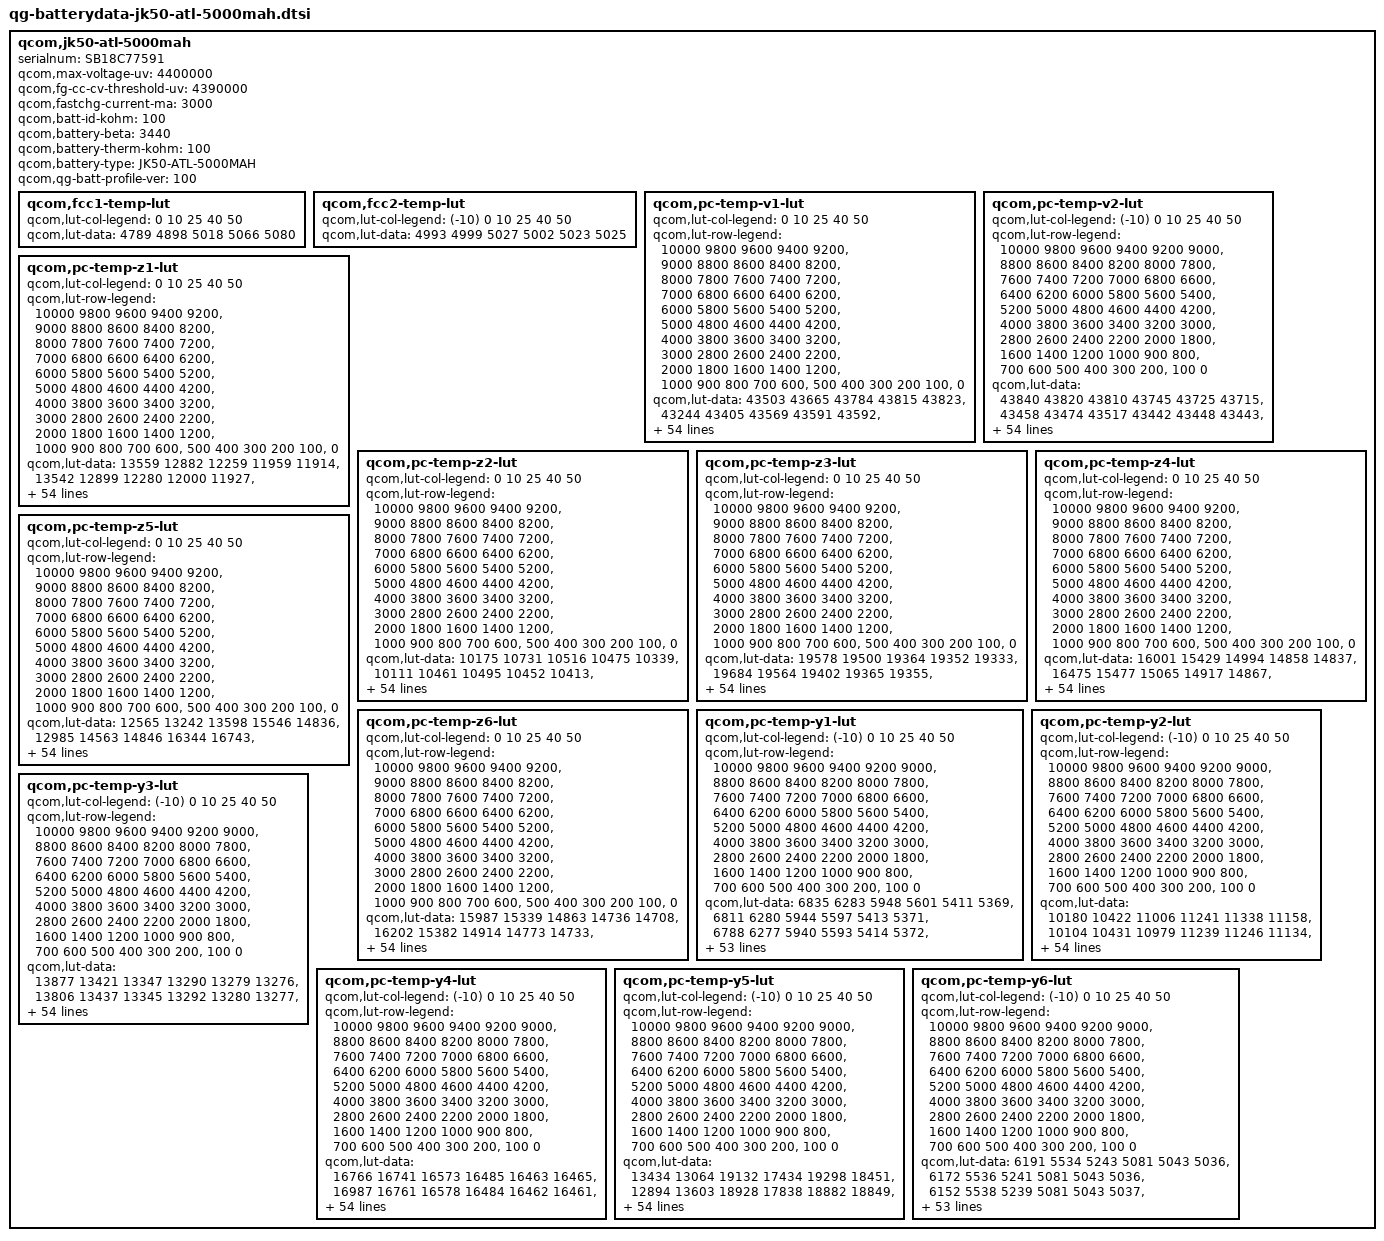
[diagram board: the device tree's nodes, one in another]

qcom,jk50-atl-5000mah {
    /* 4614914_Huaqin_QL1899_MOTO_5000mAH_PMI632_averaged_MasterSlave_Jun15th2020 */
    serialnum = "SB18C77591";
    qcom,max-voltage-uv = <4400000>;
    qcom,fg-cc-cv-threshold-uv = <4390000>;
    qcom,fastchg-current-ma = <3000>;
    qcom,batt-id-kohm = <100>;
    qcom,battery-beta = <3440>;
    qcom,battery-therm-kohm = <100>;
    qcom,battery-type = "JK50-ATL-5000MAH";
    qcom,qg-batt-profile-ver = <100>;

	qcom,fcc1-temp-lut {
		qcom,lut-col-legend = <0 10 25 40 50>;
		qcom,lut-data = <4789 4898 5018 5066 5080>;
	};

	qcom,fcc2-temp-lut {
		qcom,lut-col-legend = <(-10) 0 10 25 40 50>;
		qcom,lut-data = <4993 4999 5027 5002 5023 5025>;
	};

	qcom,pc-temp-v1-lut {
		qcom,lut-col-legend = <0 10 25 40 50>;
		qcom,lut-row-legend = <10000 9800 9600 9400 9200>,
			<9000 8800 8600 8400 8200>,
			<8000 7800 7600 7400 7200>,
			<7000 6800 6600 6400 6200>,
			<6000 5800 5600 5400 5200>,
			<5000 4800 4600 4400 4200>,
			<4000 3800 3600 3400 3200>,
			<3000 2800 2600 2400 2200>,
			<2000 1800 1600 1400 1200>,
			<1000 900 800 700 600>,
			<500 400 300 200 100>,
			<0>;
		qcom,lut-data = <43503 43665 43784 43815 43823>,
			<43244 43405 43569 43591 43592>,
			<42990 43154 43314 43362 43368>,
			<42743 42911 43067 43131 43145>,
			<42505 42674 42828 42897 42915>,
			<42275 42439 42590 42660 42681>,
			<42049 42209 42357 42426 42448>,
			<41829 41983 42125 42191 42216>,
			<41615 41760 41896 41959 41985>,
			<41412 41542 41666 41732 41754>,
			<41220 41336 41443 41507 41525>,
			<41022 41138 41233 41290 41303>,
			<40809 40935 41033 41076 41087>,
			<40591 40723 40829 40868 40879>,
			<40372 40511 40618 40660 40674>,
			<40149 40304 40412 40457 40476>,
			<39953 40102 40216 40267 40286>,
			<39802 39928 40029 40089 40106>,
			<39673 39786 39866 39919 39933>,
			<39547 39657 39731 39768 39778>,
			<39422 39522 39588 39615 39624>,
			<39301 39385 39390 39404 39423>,
			<39181 39233 39157 39119 39152>,
			<39063 39033 38950 38901 38930>,
			<38949 38821 38755 38775 38799>,
			<38840 38664 38607 38676 38695>,
			<38735 38539 38524 38581 38595>,
			<38633 38446 38464 38493 38502>,
			<38533 38383 38401 38410 38414>,
			<38445 38336 38336 38331 38328>,
			<38376 38294 38277 38258 38248>,
			<38318 38257 38224 38190 38176>,
			<38269 38222 38176 38128 38112>,
			<38231 38189 38132 38071 38049>,
			<38197 38159 38092 38022 37991>,
			<38163 38125 38051 37975 37935>,
			<38132 38089 38010 37927 37878>,
			<38094 38047 37965 37878 37822>,
			<38042 37986 37904 37813 37751>,
			<37976 37903 37818 37719 37656>,
			<37889 37806 37716 37612 37548>,
			<37765 37690 37604 37501 37436>,
			<37625 37555 37474 37376 37312>,
			<37466 37391 37315 37221 37153>,
			<37332 37252 37172 37083 37019>,
			<37235 37163 37080 36998 36939>,
			<37207 37133 37054 36970 36910>,
			<37184 37116 37037 36953 36892>,
			<37154 37091 37019 36933 36872>,
			<37100 37049 36971 36875 36802>,
			<36895 36830 36732 36619 36518>,
			<36447 36388 36298 36181 36077>,
			<35869 35813 35725 35606 35502>,
			<35085 35027 34941 34820 34713>,
			<33848 33792 33723 33601 33485>,
			<30000 30000 30000 30000 30000>;
	};

	qcom,pc-temp-v2-lut {
		qcom,lut-col-legend = <(-10) 0 10 25 40 50>;
		qcom,lut-row-legend = <10000 9800 9600 9400 9200 9000>,
			<8800 8600 8400 8200 8000 7800>,
			<7600 7400 7200 7000 6800 6600>,
			<6400 6200 6000 5800 5600 5400>,
			<5200 5000 4800 4600 4400 4200>,
			<4000 3800 3600 3400 3200 3000>,
			<2800 2600 2400 2200 2000 1800>,
			<1600 1400 1200 1000 900 800>,
			<700 600 500 400 300 200>,
			<100 0>;
		qcom,lut-data = <43840 43820 43810 43745 43725 43715>,
			<43458 43474 43517 43442 43448 43443>,
			<43111 43158 43238 43158 43183 43182>,
			<42801 42876 42974 42897 42931 42934>,
			<42521 42626 42724 42658 42692 42697>,
			<42275 42384 42481 42423 42457 42464>,
			<42072 42142 42241 42188 42222 42229>,
			<41886 41905 42006 41955 41990 41996>,
			<41651 41668 41778 41726 41761 41766>,
			<41346 41429 41556 41500 41534 41539>,
			<41111 41209 41340 41280 41311 41316>,
			<41007 41029 41133 41068 41091 41098>,
			<40924 40858 40930 40861 40876 40883>,
			<40722 40648 40723 40656 40671 40677>,
			<40242 40393 40513 40449 40472 40474>,
			<39810 40129 40297 40249 40279 40281>,
			<39580 39859 40063 40057 40090 40096>,
			<39401 39599 39827 39873 39909 39919>,
			<39230 39399 39611 39703 39742 39752>,
			<39075 39242 39408 39552 39590 39596>,
			<38921 39092 39219 39384 39419 39422>,
			<38755 38930 39036 39155 39191 39195>,
			<38594 38772 38869 38912 38953 38960>,
			<38457 38629 38720 38733 38773 38781>,
			<38338 38502 38588 38594 38624 38632>,
			<38239 38378 38467 38474 38497 38504>,
			<38160 38244 38358 38367 38388 38393>,
			<38093 38120 38257 38273 38292 38295>,
			<38030 38037 38165 38185 38204 38205>,
			<37971 37978 38079 38104 38125 38124>,
			<37915 37929 38001 38031 38053 38051>,
			<37860 37890 37926 37963 37988 37983>,
			<37808 37854 37860 37902 37927 37919>,
			<37751 37812 37810 37843 37862 37851>,
			<37694 37765 37771 37790 37795 37780>,
			<37634 37715 37731 37736 37720 37698>,
			<37571 37668 37693 37678 37633 37595>,
			<37506 37618 37651 37617 37543 37487>,
			<37441 37556 37596 37550 37462 37400>,
			<37376 37483 37528 37478 37387 37324>,
			<37311 37400 37448 37397 37307 37243>,
			<37248 37303 37350 37300 37216 37154>,
			<37183 37193 37234 37187 37109 37048>,
			<37116 37075 37090 37048 36971 36908>,
			<37039 36971 36968 36931 36864 36804>,
			<36935 36879 36889 36877 36820 36763>,
			<36880 36839 36863 36860 36806 36753>,
			<36809 36795 36840 36840 36793 36741>,
			<36721 36736 36799 36811 36766 36709>,
			<36576 36641 36718 36740 36678 36602>,
			<36330 36433 36479 36480 36374 36272>,
			<35922 36019 35998 36004 35881 35772>,
			<35320 35416 35350 35379 35239 35123>,
			<34438 34555 34477 34547 34359 34234>,
			<33056 33207 33195 33293 33080 32922>,
			<28273 28027 28006 28026 28120 28083>;
	};

	qcom,pc-temp-z1-lut {
		qcom,lut-col-legend = <0 10 25 40 50>;
		qcom,lut-row-legend = <10000 9800 9600 9400 9200>,
			<9000 8800 8600 8400 8200>,
			<8000 7800 7600 7400 7200>,
			<7000 6800 6600 6400 6200>,
			<6000 5800 5600 5400 5200>,
			<5000 4800 4600 4400 4200>,
			<4000 3800 3600 3400 3200>,
			<3000 2800 2600 2400 2200>,
			<2000 1800 1600 1400 1200>,
			<1000 900 800 700 600>,
			<500 400 300 200 100>,
			<0>;
		qcom,lut-data = <13559 12882 12259 11959 11914>,
			<13542 12899 12280 12000 11927>,
			<13561 12901 12284 12004 11933>,
			<13572 12894 12284 12006 11937>,
			<13562 12884 12278 12006 11938>,
			<13543 12869 12272 12005 11937>,
			<13536 12850 12267 12003 11937>,
			<13541 12846 12263 12001 11939>,
			<13548 12853 12258 11999 11941>,
			<13548 12860 12253 12001 11943>,
			<13539 12854 12249 12005 11946>,
			<13526 12838 12250 12007 11950>,
			<13499 12819 12253 12009 11953>,
			<13468 12794 12254 12010 11956>,
			<13452 12772 12251 12010 11956>,
			<13438 12763 12249 12010 11957>,
			<13428 12757 12249 12011 11958>,
			<13427 12754 12250 12012 11960>,
			<13428 12761 12251 12013 11961>,
			<13433 12772 12255 12016 11962>,
			<13448 12780 12260 12018 11963>,
			<13463 12787 12264 12018 11963>,
			<13454 12792 12268 12018 11964>,
			<13424 12797 12272 12018 11964>,
			<13407 12802 12276 12020 11966>,
			<13409 12806 12280 12024 11968>,
			<13410 12812 12284 12027 11971>,
			<13412 12816 12287 12031 11974>,
			<13413 12818 12292 12035 11978>,
			<13415 12819 12296 12039 11981>,
			<13425 12822 12301 12043 11983>,
			<13446 12834 12307 12046 11986>,
			<13455 12843 12314 12049 11990>,
			<13446 12846 12320 12053 11993>,
			<13436 12848 12325 12059 11998>,
			<13440 12852 12331 12064 12002>,
			<13452 12866 12338 12068 12005>,
			<13468 12879 12345 12072 12008>,
			<13499 12886 12352 12076 12011>,
			<13530 12894 12359 12079 12013>,
			<13534 12904 12367 12082 12016>,
			<13518 12922 12374 12086 12019>,
			<13515 12932 12382 12091 12022>,
			<13534 12928 12388 12095 12024>,
			<13518 12934 12396 12100 12028>,
			<13513 12936 12403 12104 12029>,
			<13523 12924 12402 12103 12030>,
			<13542 12928 12400 12105 12030>,
			<13528 12928 12407 12107 12032>,
			<13517 12947 12407 12110 12035>,
			<13524 12957 12412 12115 12039>,
			<13549 12959 12435 12124 12047>,
			<13581 13005 12443 12134 12059>,
			<13618 13043 12469 12153 12077>,
			<13618 13043 12469 12153 12077>,
			<13618 13043 12469 12153 12077>;
	};

	qcom,pc-temp-z2-lut {
		qcom,lut-col-legend = <0 10 25 40 50>;
		qcom,lut-row-legend = <10000 9800 9600 9400 9200>,
			<9000 8800 8600 8400 8200>,
			<8000 7800 7600 7400 7200>,
			<7000 6800 6600 6400 6200>,
			<6000 5800 5600 5400 5200>,
			<5000 4800 4600 4400 4200>,
			<4000 3800 3600 3400 3200>,
			<3000 2800 2600 2400 2200>,
			<2000 1800 1600 1400 1200>,
			<1000 900 800 700 600>,
			<500 400 300 200 100>,
			<0>;
		qcom,lut-data = <10175 10731 10516 10475 10339>,
			<10111 10461 10495 10452 10413>,
			<10212 10361 10534 10522 10425>,
			<10302 10353 10543 10565 10448>,
			<10335 10345 10524 10559 10467>,
			<10356 10319 10501 10541 10485>,
			<10363 10284 10567 10530 10493>,
			<10361 10270 10779 10506 10482>,
			<10358 10266 10851 10488 10469>,
			<10357 10262 10634 10479 10469>,
			<10352 10258 10415 10466 10475>,
			<10345 10254 10483 10461 10478>,
			<10323 10251 10711 10459 10468>,
			<10292 10250 10819 10459 10454>,
			<10268 10249 10847 10465 10427>,
			<10247 10254 10862 10470 10389>,
			<10235 10272 10773 10446 10365>,
			<10234 10295 10545 10368 10346>,
			<10236 10324 10469 10326 10336>,
			<10236 10354 10486 10340 10352>,
			<10233 10376 10514 10372 10394>,
			<10229 10392 10576 10460 10484>,
			<10223 10410 10663 10690 10699>,
			<10212 10438 10680 10803 10815>,
			<10207 10468 10624 10630 10668>,
			<10212 10479 10567 10419 10470>,
			<10221 10484 10543 10400 10452>,
			<10227 10485 10526 10416 10494>,
			<10231 10482 10527 10439 10546>,
			<10235 10479 10561 10477 10618>,
			<10238 10474 10596 10524 10678>,
			<10240 10468 10612 10578 10648>,
			<10244 10463 10623 10646 10521>,
			<10247 10463 10625 10667 10433>,
			<10252 10464 10618 10611 10382>,
			<10258 10466 10614 10551 10350>,
			<10268 10481 10618 10538 10362>,
			<10279 10499 10630 10540 10409>,
			<10291 10512 10646 10561 10462>,
			<10305 10523 10671 10661 10548>,
			<10320 10532 10691 10745 10611>,
			<10335 10538 10698 10733 10586>,
			<10360 10546 10701 10710 10542>,
			<10417 10557 10691 10698 10558>,
			<10726 10713 10719 10667 10554>,
			<10783 10783 10765 10608 10566>,
			<10691 10788 10767 10595 10510>,
			<10649 10918 10770 10625 10548>,
			<10662 10966 10819 10640 10570>,
			<10598 11127 10858 10734 10654>,
			<10572 10989 10841 10710 10508>,
			<10521 11002 10807 10477 10311>,
			<10315 10800 10697 10411 10238>,
			<10113 10604 10600 10323 10187>,
			<10113 10604 10600 10323 10187>,
			<10113 10604 10600 10323 10187>;
	};

	qcom,pc-temp-z3-lut {
		qcom,lut-col-legend = <0 10 25 40 50>;
		qcom,lut-row-legend = <10000 9800 9600 9400 9200>,
			<9000 8800 8600 8400 8200>,
			<8000 7800 7600 7400 7200>,
			<7000 6800 6600 6400 6200>,
			<6000 5800 5600 5400 5200>,
			<5000 4800 4600 4400 4200>,
			<4000 3800 3600 3400 3200>,
			<3000 2800 2600 2400 2200>,
			<2000 1800 1600 1400 1200>,
			<1000 900 800 700 600>,
			<500 400 300 200 100>,
			<0>;
		qcom,lut-data = <19578 19500 19364 19352 19333>,
			<19684 19564 19402 19365 19355>,
			<19730 19598 19447 19381 19366>,
			<19749 19620 19464 19390 19372>,
			<19731 19630 19466 19396 19379>,
			<19694 19627 19467 19401 19386>,
			<19673 19619 19471 19403 19389>,
			<19661 19613 19481 19406 19391>,
			<19655 19609 19485 19408 19392>,
			<19655 19605 19472 19407 19395>,
			<19656 19599 19460 19404 19398>,
			<19657 19589 19459 19400 19398>,
			<19665 19582 19462 19395 19391>,
			<19678 19579 19463 19390 19382>,
			<19684 19576 19461 19389 19377>,
			<19689 19570 19458 19387 19373>,
			<19692 19557 19451 19384 19369>,
			<19684 19543 19438 19377 19366>,
			<19669 19524 19427 19369 19363>,
			<19662 19509 19414 19362 19356>,
			<19663 19508 19406 19357 19348>,
			<19668 19512 19415 19360 19348>,
			<19676 19519 19435 19374 19357>,
			<19691 19534 19441 19382 19363>,
			<19702 19552 19436 19369 19349>,
			<19707 19556 19431 19352 19331>,
			<19710 19556 19424 19348 19328>,
			<19713 19556 19417 19346 19330>,
			<19716 19554 19416 19346 19334>,
			<19719 19549 19417 19351 19350>,
			<19716 19543 19418 19360 19368>,
			<19708 19537 19420 19369 19370>,
			<19699 19532 19422 19379 19371>,
			<19689 19526 19422 19382 19371>,
			<19679 19521 19422 19379 19366>,
			<19668 19518 19422 19375 19360>,
			<19656 19516 19420 19370 19355>,
			<19645 19515 19418 19363 19350>,
			<19634 19513 19416 19361 19346>,
			<19624 19509 19414 19361 19343>,
			<19616 19505 19412 19360 19341>,
			<19611 19498 19407 19360 19342>,
			<19604 19492 19402 19360 19344>,
			<19593 19488 19400 19360 19349>,
			<19502 19457 19392 19356 19350>,
			<19448 19429 19379 19343 19336>,
			<19380 19420 19373 19342 19333>,
			<19323 19382 19360 19332 19326>,
			<19317 19378 19346 19332 19320>,
			<19312 19331 19350 19324 19318>,
			<19317 19343 19362 19328 19343>,
			<19336 19356 19362 19347 19357>,
			<19345 19336 19358 19351 19352>,
			<19355 19336 19352 19353 19352>,
			<19355 19336 19352 19353 19352>,
			<19355 19336 19352 19353 19352>;
	};

	qcom,pc-temp-z4-lut {
		qcom,lut-col-legend = <0 10 25 40 50>;
		qcom,lut-row-legend = <10000 9800 9600 9400 9200>,
			<9000 8800 8600 8400 8200>,
			<8000 7800 7600 7400 7200>,
			<7000 6800 6600 6400 6200>,
			<6000 5800 5600 5400 5200>,
			<5000 4800 4600 4400 4200>,
			<4000 3800 3600 3400 3200>,
			<3000 2800 2600 2400 2200>,
			<2000 1800 1600 1400 1200>,
			<1000 900 800 700 600>,
			<500 400 300 200 100>,
			<0>;
		qcom,lut-data = <16001 15429 14994 14858 14837>,
			<16475 15477 15065 14917 14867>,
			<16312 15462 15035 14898 14857>,
			<16124 15318 14998 14873 14841>,
			<15969 15168 14946 14849 14824>,
			<15819 15083 14892 14824 14805>,
			<15691 15016 14843 14801 14786>,
			<15581 14961 14793 14780 14769>,
			<15484 14915 14768 14762 14753>,
			<15403 14877 14762 14746 14737>,
			<15331 14850 14758 14733 14721>,
			<15266 14828 14740 14722 14711>,
			<15203 14808 14705 14712 14705>,
			<15146 14788 14688 14704 14700>,
			<15099 14772 14683 14697 14696>,
			<15061 14761 14679 14692 14693>,
			<15027 14754 14680 14688 14688>,
			<14994 14748 14687 14685 14683>,
			<14963 14741 14687 14682 14679>,
			<14933 14735 14682 14679 14676>,
			<14905 14725 14679 14676 14673>,
			<14877 14712 14690 14690 14684>,
			<14847 14706 14721 14753 14744>,
			<14816 14727 14752 14795 14791>,
			<14793 14763 14795 14808 14805>,
			<14777 14782 14822 14814 14813>,
			<14765 14795 14816 14812 14811>,
			<14762 14801 14800 14800 14797>,
			<14764 14794 14786 14785 14778>,
			<14766 14780 14772 14767 14749>,
			<14766 14767 14758 14747 14719>,
			<14766 14756 14744 14726 14702>,
			<14765 14745 14730 14705 14690>,
			<14762 14736 14717 14693 14683>,
			<14757 14727 14706 14686 14679>,
			<14754 14719 14697 14682 14677>,
			<14751 14709 14692 14680 14677>,
			<14748 14703 14688 14680 14677>,
			<14744 14703 14688 14680 14678>,
			<14740 14704 14693 14690 14691>,
			<14737 14704 14697 14698 14703>,
			<14736 14704 14695 14694 14699>,
			<14731 14703 14693 14689 14692>,
			<14719 14700 14691 14689 14691>,
			<14724 14685 14680 14682 14682>,
			<14757 14686 14666 14670 14668>,
			<14831 14690 14665 14663 14665>,
			<14891 14722 14667 14657 14654>,
			<14890 14719 14670 14639 14639>,
			<14886 14766 14658 14641 14632>,
			<14879 14759 14667 14670 14650>,
			<14878 14759 14679 14665 14651>,
			<14891 14794 14688 14667 14660>,
			<14900 14803 14701 14668 14663>,
			<14900 14803 14701 14668 14663>,
			<14900 14803 14701 14668 14663>;
	};

	qcom,pc-temp-z5-lut {
		qcom,lut-col-legend = <0 10 25 40 50>;
		qcom,lut-row-legend = <10000 9800 9600 9400 9200>,
			<9000 8800 8600 8400 8200>,
			<8000 7800 7600 7400 7200>,
			<7000 6800 6600 6400 6200>,
			<6000 5800 5600 5400 5200>,
			<5000 4800 4600 4400 4200>,
			<4000 3800 3600 3400 3200>,
			<3000 2800 2600 2400 2200>,
			<2000 1800 1600 1400 1200>,
			<1000 900 800 700 600>,
			<500 400 300 200 100>,
			<0>;
		qcom,lut-data = <12565 13242 13598 15546 14836>,
			<12985 14563 14846 16344 16743>,
			<13490 15501 16834 17448 17647>,
			<13868 16216 17839 18166 18202>,
			<14019 16730 18227 18710 18931>,
			<14124 17045 18513 19212 19688>,
			<14241 17281 19316 19612 20362>,
			<14376 17613 21087 20444 20865>,
			<14514 18208 21933 21194 21460>,
			<14647 18803 21752 21482 22959>,
			<14781 19152 21466 21814 25191>,
			<14941 19502 22900 22138 25913>,
			<15190 19962 26863 22632 25623>,
			<15494 21302 29129 23317 25350>,
			<15780 22738 30230 24605 25529>,
			<16120 23072 31060 25955 25964>,
			<16338 22851 30678 25973 26600>,
			<16346 22524 28616 25082 27873>,
			<16310 21899 27277 24591 28715>,
			<16404 21303 26559 24846 28228>,
			<16926 21908 26167 25521 27369>,
			<17830 25290 35457 28799 28090>,
			<19296 30381 54726 38845 32559>,
			<21951 43206 59411 43795 35192>,
			<24859 57985 50540 34860 28904>,
			<27950 60255 40413 23097 19767>,
			<31351 56768 34180 19994 17571>,
			<35005 52493 29162 18646 16921>,
			<39622 48672 27560 18278 16760>,
			<42404 44761 27075 18842 18602>,
			<42049 41495 26883 19986 21625>,
			<40830 38560 27440 22440 24051>,
			<39331 36449 28824 26935 26370>,
			<37080 35134 30338 29849 28205>,
			<34524 34053 32297 31511 29813>,
			<32261 33840 34106 32525 30842>,
			<29854 35274 35571 32557 30972>,
			<28277 36822 36736 32038 30955>,
			<27457 37146 36880 31660 30719>,
			<26915 37316 36230 31493 28810>,
			<26937 37133 35137 31272 26485>,
			<27775 33679 32136 29422 24857>,
			<29117 31565 29160 26828 23766>,
			<31207 32122 28644 26539 25884>,
			<24080 30617 28872 26485 26840>,
			<19272 24479 27251 22831 22017>,
			<14901 22384 24577 22682 20975>,
			<12391 16480 21706 20591 20331>,
			<12280 16314 18193 23118 21444>,
			<12238 13536 20088 21235 22822>,
			<12452 14257 21525 18276 25323>,
			<12784 14471 18734 19108 24655>,
			<12602 13207 17295 18591 20263>,
			<12497 12911 15872 18021 18194>,
			<12497 12911 15872 18021 18194>,
			<12497 12911 15872 18021 18194>;
	};

	qcom,pc-temp-z6-lut {
		qcom,lut-col-legend = <0 10 25 40 50>;
		qcom,lut-row-legend = <10000 9800 9600 9400 9200>,
			<9000 8800 8600 8400 8200>,
			<8000 7800 7600 7400 7200>,
			<7000 6800 6600 6400 6200>,
			<6000 5800 5600 5400 5200>,
			<5000 4800 4600 4400 4200>,
			<4000 3800 3600 3400 3200>,
			<3000 2800 2600 2400 2200>,
			<2000 1800 1600 1400 1200>,
			<1000 900 800 700 600>,
			<500 400 300 200 100>,
			<0>;
		qcom,lut-data = <15987 15339 14863 14736 14708>,
			<16202 15382 14914 14773 14733>,
			<16132 15379 14920 14772 14734>,
			<16042 15318 14918 14769 14735>,
			<15947 15249 14897 14764 14733>,
			<15843 15202 14868 14755 14729>,
			<15761 15161 14850 14746 14723>,
			<15695 15128 14834 14739 14718>,
			<15640 15100 14821 14732 14712>,
			<15596 15077 14811 14726 14707>,
			<15558 15058 14802 14719 14703>,
			<15523 15041 14792 14712 14698>,
			<15486 15025 14781 14706 14692>,
			<15451 15006 14774 14700 14686>,
			<15426 14990 14770 14696 14681>,
			<15406 14978 14766 14692 14677>,
			<15387 14968 14762 14688 14673>,
			<15365 14958 14758 14683 14669>,
			<15342 14947 14752 14678 14665>,
			<15325 14937 14744 14672 14659>,
			<15312 14935 14739 14668 14654>,
			<15302 14934 14748 14677 14660>,
			<15293 14934 14772 14713 14692>,
			<15286 14951 14791 14733 14713>,
			<15281 14978 14807 14731 14711>,
			<15279 14991 14816 14727 14707>,
			<15277 14998 14812 14723 14704>,
			<15278 15002 14802 14717 14699>,
			<15282 14998 14796 14713 14695>,
			<15285 14991 14791 14709 14692>,
			<15285 14984 14787 14705 14688>,
			<15282 14978 14783 14702 14684>,
			<15279 14972 14779 14699 14680>,
			<15275 14967 14775 14696 14676>,
			<15269 14963 14771 14692 14672>,
			<15265 14960 14768 14688 14669>,
			<15262 14958 14766 14684 14666>,
			<15259 14957 14764 14681 14663>,
			<15257 14957 14765 14681 14663>,
			<15255 14960 14767 14685 14667>,
			<15255 14961 14769 14689 14670>,
			<15259 14961 14768 14688 14669>,
			<15260 14962 14766 14685 14668>,
			<15257 14963 14766 14686 14670>,
			<15227 14950 14760 14682 14667>,
			<15215 14937 14749 14670 14654>,
			<15211 14934 14745 14667 14651>,
			<15208 14929 14739 14660 14643>,
			<15206 14927 14733 14651 14633>,
			<15205 14926 14732 14649 14630>,
			<15213 14935 14744 14664 14651>,
			<15231 14950 14753 14674 14662>,
			<15254 14964 14759 14680 14666>,
			<15285 14983 14768 14686 14672>,
			<15285 14983 14768 14686 14672>,
			<15285 14983 14768 14686 14672>;
	};

	qcom,pc-temp-y1-lut {
		qcom,lut-col-legend = <(-10) 0 10 25 40 50>;
		qcom,lut-row-legend = <10000 9800 9600 9400 9200 9000>,
			<8800 8600 8400 8200 8000 7800>,
			<7600 7400 7200 7000 6800 6600>,
			<6400 6200 6000 5800 5600 5400>,
			<5200 5000 4800 4600 4400 4200>,
			<4000 3800 3600 3400 3200 3000>,
			<2800 2600 2400 2200 2000 1800>,
			<1600 1400 1200 1000 900 800>,
			<700 600 500 400 300 200>,
			<100 0>;
		qcom,lut-data = <6835 6283 5948 5601 5411 5369>,
			<6811 6280 5944 5597 5413 5371>,
			<6788 6277 5940 5593 5414 5372>,
			<6768 6274 5936 5589 5415 5371>,
			<6755 6271 5933 5585 5415 5370>,
			<6750 6268 5930 5582 5415 5369>,
			<6756 6267 5928 5580 5413 5367>,
			<6765 6266 5926 5577 5410 5364>,
			<6761 6263 5924 5576 5409 5363>,
			<6739 6260 5921 5576 5408 5364>,
			<6726 6258 5918 5575 5408 5366>,
			<6729 6267 5917 5571 5407 5368>,
			<6736 6281 5916 5567 5406 5370>,
			<6744 6284 5916 5566 5405 5369>,
			<6755 6284 5918 5567 5405 5366>,
			<6761 6286 5918 5568 5405 5364>,
			<6754 6289 5915 5570 5406 5366>,
			<6744 6293 5912 5572 5406 5368>,
			<6748 6294 5913 5573 5406 5368>,
			<6780 6293 5918 5575 5407 5369>,
			<6802 6292 5921 5577 5408 5369>,
			<6779 6289 5917 5581 5410 5369>,
			<6741 6287 5913 5585 5412 5368>,
			<6736 6292 5914 5588 5413 5369>,
			<6752 6308 5919 5590 5415 5372>,
			<6767 6317 5922 5592 5417 5375>,
			<6770 6303 5922 5597 5420 5377>,
			<6766 6283 5923 5602 5423 5379>,
			<6753 6280 5924 5607 5426 5381>,
			<6725 6286 5927 5611 5428 5383>,
			<6708 6291 5929 5616 5431 5385>,
			<6724 6294 5937 5620 5435 5387>,
			<6753 6295 5946 5625 5439 5390>,
			<6757 6295 5950 5629 5442 5392>,
			<6731 6292 5956 5634 5445 5395>,
			<6710 6288 5958 5637 5447 5396>,
			<6707 6281 5959 5640 5448 5397>,
			<6706 6273 5961 5642 5449 5397>,
			<6703 6271 5966 5643 5450 5399>,
			<6689 6276 5973 5647 5451 5401>,
			<6681 6281 5975 5649 5451 5404>,
			<6689 6279 5969 5655 5453 5406>,
			<6703 6274 5967 5659 5455 5406>,
			<6697 6275 5974 5665 5458 5407>,
			<6690 6290 5992 5671 5463 5410>,
			<6710 6294 5981 5682 5468 5412>,
			<6749 6301 5982 5676 5468 5411>,
			<6718 6305 5991 5679 5467 5410>,
			<6737 6284 5991 5680 5467 5412>,
			<6736 6309 5987 5685 5467 5413>,
			<6740 6299 5995 5685 5470 5416>,
			<6767 6308 6012 5698 5477 5421>,
			<6756 6334 6030 5713 5486 5428>,
			<6859 6360 6044 5746 5500 5438>,
			<6859 6360 6044 5746 5500 5438>,
			<6859 6360 6044 5746 5500 5438>;
	};

	qcom,pc-temp-y2-lut {
		qcom,lut-col-legend = <(-10) 0 10 25 40 50>;
		qcom,lut-row-legend = <10000 9800 9600 9400 9200 9000>,
			<8800 8600 8400 8200 8000 7800>,
			<7600 7400 7200 7000 6800 6600>,
			<6400 6200 6000 5800 5600 5400>,
			<5200 5000 4800 4600 4400 4200>,
			<4000 3800 3600 3400 3200 3000>,
			<2800 2600 2400 2200 2000 1800>,
			<1600 1400 1200 1000 900 800>,
			<700 600 500 400 300 200>,
			<100 0>;
		qcom,lut-data = <10180 10422 11006 11241 11338 11158>,
			<10104 10431 10979 11239 11246 11134>,
			<10071 10444 10947 11225 11156 11098>,
			<10071 10459 10917 11205 11078 11058>,
			<10093 10476 10890 11182 11024 11021>,
			<10127 10491 10873 11161 11005 10997>,
			<10190 10510 10862 11137 11025 10970>,
			<10286 10529 10854 11110 11055 10939>,
			<10404 10536 10855 11094 11046 10921>,
			<10576 10534 10865 11077 10976 10911>,
			<10670 10538 10872 11069 10935 10907>,
			<10649 10673 10870 11070 10958 10908>,
			<10614 10874 10867 11073 10994 10911>,
			<10628 10909 10897 11081 11006 10910>,
			<10745 10890 11019 11105 11029 10905>,
			<10823 10877 11090 11136 11058 10904>,
			<10456 10888 11093 11173 11094 10928>,
			<9860 10915 11095 11218 11145 10976>,
			<9719 10947 11104 11274 11224 11062>,
			<9707 10996 11130 11352 11348 11233>,
			<9699 11047 11156 11394 11405 11318>,
			<9691 11104 11181 11356 11356 11276>,
			<9686 11153 11207 11297 11283 11212>,
			<9681 11151 11233 11291 11251 11175>,
			<9678 11103 11259 11326 11235 11148>,
			<9676 11073 11283 11363 11241 11139>,
			<9673 11098 11308 11395 11290 11165>,
			<9672 11136 11327 11427 11354 11208>,
			<9670 11141 11330 11440 11396 11255>,
			<9669 11120 11330 11446 11434 11330>,
			<9668 11091 11331 11453 11472 11375>,
			<9667 11057 11336 11474 11521 11388>,
			<9666 11001 11340 11501 11562 11398>,
			<9665 10808 11332 11513 11568 11435>,
			<9665 10191 11307 11519 11542 11512>,
			<9664 9777 11281 11519 11506 11541>,
			<9663 9727 11252 11502 11441 11482>,
			<9663 9700 11221 11474 11376 11398>,
			<9662 9688 11194 11451 11353 11347>,
			<9662 9681 11167 11429 11338 11300>,
			<9661 9675 11129 11410 11336 11288>,
			<9661 9671 11067 11392 11388 11313>,
			<9660 9667 10997 11367 11418 11316>,
			<9660 9665 10927 11283 11323 11194>,
			<9660 9662 10818 11239 11249 11079>,
			<9660 9662 10753 11248 11160 11004>,
			<9659 9661 10697 11219 11142 11000>,
			<9659 9660 10667 11196 11155 11097>,
			<9659 9659 10650 11217 11184 11084>,
			<9658 9658 10628 11224 11231 11033>,
			<9658 9657 10269 11212 11121 10937>,
			<9657 9657 9991 11123 11045 10854>,
			<9655 9656 9690 11016 10963 10785>,
			<9651 9654 9668 10943 10818 10673>,
			<9651 9654 9668 10943 10818 10673>,
			<9651 9654 9668 10943 10818 10673>;
	};

	qcom,pc-temp-y3-lut {
		qcom,lut-col-legend = <(-10) 0 10 25 40 50>;
		qcom,lut-row-legend = <10000 9800 9600 9400 9200 9000>,
			<8800 8600 8400 8200 8000 7800>,
			<7600 7400 7200 7000 6800 6600>,
			<6400 6200 6000 5800 5600 5400>,
			<5200 5000 4800 4600 4400 4200>,
			<4000 3800 3600 3400 3200 3000>,
			<2800 2600 2400 2200 2000 1800>,
			<1600 1400 1200 1000 900 800>,
			<700 600 500 400 300 200>,
			<100 0>;
		qcom,lut-data = <13877 13421 13347 13290 13279 13276>,
			<13806 13437 13345 13292 13280 13277>,
			<13751 13448 13344 13294 13280 13278>,
			<13713 13454 13344 13295 13281 13279>,
			<13689 13458 13344 13296 13282 13280>,
			<13682 13459 13344 13297 13283 13280>,
			<13699 13455 13345 13297 13283 13281>,
			<13726 13448 13347 13297 13284 13281>,
			<13709 13449 13349 13297 13285 13282>,
			<13588 13459 13351 13298 13286 13283>,
			<13508 13466 13353 13298 13286 13283>,
			<13510 13443 13354 13300 13287 13284>,
			<13514 13407 13354 13302 13287 13284>,
			<13513 13403 13354 13303 13288 13285>,
			<13504 13412 13352 13305 13291 13285>,
			<13491 13418 13351 13307 13293 13286>,
			<13465 13409 13348 13306 13293 13287>,
			<13436 13393 13345 13304 13293 13288>,
			<13431 13385 13341 13304 13293 13289>,
			<13435 13381 13337 13306 13292 13290>,
			<13439 13376 13333 13307 13291 13290>,
			<13440 13369 13329 13304 13288 13286>,
			<13439 13361 13326 13298 13284 13280>,
			<13436 13356 13323 13294 13282 13279>,
			<13424 13354 13321 13292 13281 13278>,
			<13416 13350 13319 13291 13280 13278>,
			<13424 13342 13317 13291 13279 13277>,
			<13441 13332 13315 13291 13279 13276>,
			<13456 13329 13315 13291 13279 13276>,
			<13472 13329 13316 13291 13279 13277>,
			<13489 13329 13316 13291 13280 13277>,
			<13511 13333 13314 13292 13281 13277>,
			<13537 13341 13312 13292 13282 13277>,
			<13561 13347 13312 13292 13282 13277>,
			<13586 13351 13313 13293 13282 13278>,
			<13613 13356 13314 13293 13281 13279>,
			<13643 13364 13317 13293 13281 13278>,
			<13678 13376 13319 13292 13280 13277>,
			<13715 13387 13321 13292 13280 13277>,
			<13755 13398 13322 13293 13281 13279>,
			<13797 13413 13323 13293 13281 13280>,
			<13842 13442 13325 13294 13282 13281>,
			<13891 13484 13326 13294 13283 13282>,
			<13943 13540 13325 13293 13280 13279>,
			<13997 13620 13327 13293 13281 13279>,
			<13953 13636 13328 13297 13284 13283>,
			<13993 13692 13333 13298 13287 13286>,
			<14058 13763 13340 13301 13292 13291>,
			<14133 13837 13349 13306 13294 13291>,
			<14218 13924 13360 13310 13294 13289>,
			<14331 14007 13369 13306 13289 13286>,
			<14499 14107 13383 13307 13290 13286>,
			<14877 14284 13441 13313 13293 13290>,
			<15973 14538 13563 13324 13298 13298>,
			<15973 14538 13563 13324 13298 13298>,
			<15973 14538 13563 13324 13298 13298>;
	};

	qcom,pc-temp-y4-lut {
		qcom,lut-col-legend = <(-10) 0 10 25 40 50>;
		qcom,lut-row-legend = <10000 9800 9600 9400 9200 9000>,
			<8800 8600 8400 8200 8000 7800>,
			<7600 7400 7200 7000 6800 6600>,
			<6400 6200 6000 5800 5600 5400>,
			<5200 5000 4800 4600 4400 4200>,
			<4000 3800 3600 3400 3200 3000>,
			<2800 2600 2400 2200 2000 1800>,
			<1600 1400 1200 1000 900 800>,
			<700 600 500 400 300 200>,
			<100 0>;
		qcom,lut-data = <16766 16741 16573 16485 16463 16465>,
			<16987 16761 16578 16484 16462 16461>,
			<17126 16781 16584 16483 16461 16459>,
			<17202 16799 16589 16483 16461 16458>,
			<17233 16815 16593 16483 16461 16458>,
			<17240 16827 16596 16484 16462 16458>,
			<17181 16837 16598 16488 16463 16459>,
			<17089 16844 16599 16493 16464 16461>,
			<17095 16841 16602 16499 16467 16463>,
			<17235 16817 16611 16505 16470 16465>,
			<17361 16802 16621 16511 16475 16467>,
			<17423 16896 16632 16517 16480 16470>,
			<17466 17042 16645 16523 16486 16474>,
			<17413 17057 16671 16532 16490 16478>,
			<17082 16977 16720 16547 16494 16484>,
			<16861 16888 16745 16563 16499 16490>,
			<16899 16808 16722 16581 16508 16496>,
			<16962 16739 16682 16598 16522 16503>,
			<16969 16721 16645 16609 16542 16517>,
			<16928 16717 16606 16619 16574 16540>,
			<16877 16712 16576 16623 16588 16551>,
			<16822 16698 16556 16577 16553 16528>,
			<16769 16677 16542 16506 16501 16495>,
			<16751 16656 16536 16484 16479 16477>,
			<16744 16635 16532 16477 16465 16464>,
			<16741 16613 16531 16474 16461 16460>,
			<16739 16586 16532 16476 16463 16462>,
			<16738 16563 16532 16480 16468 16467>,
			<16739 16561 16531 16483 16474 16471>,
			<16740 16568 16525 16489 16481 16478>,
			<16740 16575 16519 16494 16488 16485>,
			<16739 16578 16513 16499 16498 16497>,
			<16738 16581 16509 16503 16506 16506>,
			<16737 16591 16511 16504 16507 16507>,
			<16739 16625 16522 16504 16506 16507>,
			<16741 16655 16533 16503 16503 16505>,
			<16742 16670 16543 16500 16488 16487>,
			<16743 16680 16554 16494 16471 16467>,
			<16745 16687 16563 16493 16470 16466>,
			<16755 16693 16570 16493 16471 16470>,
			<16767 16695 16575 16492 16473 16474>,
			<16785 16687 16579 16496 16479 16480>,
			<16808 16675 16579 16499 16480 16481>,
			<16835 16666 16569 16496 16466 16461>,
			<16851 16669 16564 16492 16457 16452>,
			<16805 16675 16558 16489 16466 16467>,
			<16807 16685 16574 16503 16484 16492>,
			<16821 16708 16596 16523 16511 16524>,
			<16840 16744 16628 16556 16546 16556>,
			<16846 16781 16672 16583 16550 16551>,
			<16836 16793 16689 16550 16491 16484>,
			<16817 16771 16677 16525 16473 16474>,
			<16848 16758 16713 16541 16479 16476>,
			<17130 16774 16767 16586 16501 16492>,
			<17130 16774 16767 16586 16501 16492>,
			<17130 16774 16767 16586 16501 16492>;
	};

	qcom,pc-temp-y5-lut {
		qcom,lut-col-legend = <(-10) 0 10 25 40 50>;
		qcom,lut-row-legend = <10000 9800 9600 9400 9200 9000>,
			<8800 8600 8400 8200 8000 7800>,
			<7600 7400 7200 7000 6800 6600>,
			<6400 6200 6000 5800 5600 5400>,
			<5200 5000 4800 4600 4400 4200>,
			<4000 3800 3600 3400 3200 3000>,
			<2800 2600 2400 2200 2000 1800>,
			<1600 1400 1200 1000 900 800>,
			<700 600 500 400 300 200>,
			<100 0>;
		qcom,lut-data = <13434 13064 19132 17434 19298 18451>,
			<12894 13603 18928 17838 18882 18849>,
			<12644 14280 18423 18015 18430 19041>,
			<12641 14955 17816 18017 17998 19080>,
			<12846 15484 17303 17893 17641 19012>,
			<13220 15726 17082 17693 17417 18889>,
			<15636 15696 17001 17158 17327 18388>,
			<19049 15623 16878 16368 17262 17649>,
			<18992 15712 16833 15785 17059 17259>,
			<15097 16083 16916 15297 16531 17035>,
			<12523 16311 16939 14981 15985 16791>,
			<14737 15586 16673 14847 15453 16457>,
			<18445 14464 16342 14787 15023 16075>,
			<19699 15199 16430 14748 15059 15645>,
			<20142 20132 17206 14671 15469 15126>,
			<20308 23315 18323 14731 15698 14894>,
			<18089 21443 20763 15066 15513 14962>,
			<14538 18539 23242 15685 15263 15106>,
			<13957 18132 23481 17142 15314 15290>,
			<14787 18986 23086 20922 15793 15596>,
			<15346 19698 22616 23267 16550 16076>,
			<15270 19889 22045 23177 18918 17535>,
			<15060 20062 21440 22733 21424 19150>,
			<14633 20707 20993 22011 21419 19587>,
			<13562 22717 20570 20479 20224 19773>,
			<12896 23951 20344 19482 19138 19803>,
			<12905 21143 20211 19481 18144 18509>,
			<12923 16783 20158 19699 17368 16943>,
			<12932 15635 20741 19810 17343 16782>,
			<13001 15336 22502 19995 17648 16836>,
			<13107 15216 23298 20197 18074 16866>,
			<13279 16263 22072 20749 18845 16831>,
			<13495 17877 20621 21692 19757 16858>,
			<13606 17799 20253 22553 20436 17556>,
			<13584 15833 20058 23516 21080 19414>,
			<13516 14562 20012 23984 21446 20349>,
			<13429 14614 20416 23355 21219 20437>,
			<13310 14712 20860 22224 20781 20492>,
			<13228 14686 20777 21712 20535 20666>,
			<13085 14578 20337 21241 20334 21043>,
			<12979 14502 20091 20844 20413 21289>,
			<12991 14586 19895 20469 20503 21392>,
			<13060 14630 19620 19842 20081 21406>,
			<13314 14239 18754 18284 18791 20608>,
			<13693 13982 18094 17891 18484 18295>,
			<13763 13647 17293 19112 17493 17420>,
			<14098 13920 17071 18112 17239 17316>,
			<14262 14205 17479 17777 18110 17541>,
			<14613 14293 17686 18174 17915 16765>,
			<14702 14795 18529 18939 17846 16197>,
			<14793 15035 17656 19094 18244 17037>,
			<14254 14357 15585 20285 20035 17161>,
			<13256 14069 14394 20408 20109 18408>,
			<11830 13515 14375 22132 22495 24297>,
			<11830 13515 14375 22132 22495 24297>,
			<11830 13515 14375 22132 22495 24297>;
	};

	qcom,pc-temp-y6-lut {
		qcom,lut-col-legend = <(-10) 0 10 25 40 50>;
		qcom,lut-row-legend = <10000 9800 9600 9400 9200 9000>,
			<8800 8600 8400 8200 8000 7800>,
			<7600 7400 7200 7000 6800 6600>,
			<6400 6200 6000 5800 5600 5400>,
			<5200 5000 4800 4600 4400 4200>,
			<4000 3800 3600 3400 3200 3000>,
			<2800 2600 2400 2200 2000 1800>,
			<1600 1400 1200 1000 900 800>,
			<700 600 500 400 300 200>,
			<100 0>;
		qcom,lut-data = <6191 5534 5243 5081 5043 5036>,
			<6172 5536 5241 5081 5043 5036>,
			<6152 5538 5239 5081 5043 5037>,
			<6134 5538 5237 5081 5044 5037>,
			<6119 5537 5235 5082 5044 5038>,
			<6106 5535 5233 5082 5045 5038>,
			<6098 5531 5230 5083 5046 5039>,
			<6090 5524 5228 5084 5047 5039>,
			<6074 5518 5228 5085 5048 5040>,
			<6038 5511 5230 5087 5050 5042>,
			<6017 5508 5232 5089 5051 5043>,
			<6031 5517 5233 5091 5053 5044>,
			<6054 5531 5235 5094 5055 5046>,
			<6043 5531 5240 5098 5057 5048>,
			<5957 5517 5251 5104 5060 5049>,
			<5890 5498 5256 5109 5063 5051>,
			<5875 5473 5249 5113 5066 5054>,
			<5866 5447 5236 5116 5070 5057>,
			<5859 5438 5223 5120 5075 5062>,
			<5855 5435 5208 5124 5083 5069>,
			<5850 5432 5197 5126 5086 5072>,
			<5840 5427 5189 5111 5074 5062>,
			<5829 5420 5183 5086 5056 5048>,
			<5828 5419 5180 5078 5049 5041>,
			<5832 5418 5179 5075 5044 5037>,
			<5838 5417 5178 5074 5042 5036>,
			<5851 5415 5179 5075 5043 5037>,
			<5870 5412 5180 5077 5044 5037>,
			<5888 5414 5182 5079 5046 5039>,
			<5907 5429 5183 5081 5048 5041>,
			<5926 5448 5185 5083 5051 5044>,
			<5946 5468 5185 5086 5055 5047>,
			<5968 5490 5186 5088 5058 5050>,
			<5990 5511 5189 5090 5059 5051>,
			<6012 5531 5196 5091 5058 5052>,
			<6035 5554 5205 5092 5058 5052>,
			<6062 5580 5215 5091 5053 5046>,
			<6090 5609 5226 5090 5048 5040>,
			<6122 5640 5237 5090 5048 5040>,
			<6156 5674 5248 5091 5049 5042>,
			<6193 5711 5260 5092 5050 5044>,
			<6233 5752 5275 5095 5053 5047>,
			<6278 5798 5290 5097 5053 5048>,
			<6327 5855 5305 5097 5047 5040>,
			<6377 5933 5330 5099 5047 5038>,
			<6349 5957 5332 5101 5052 5046>,
			<6382 6006 5356 5107 5059 5056>,
			<6435 6071 5387 5115 5071 5068>,
			<6500 6143 5424 5129 5082 5078>,
			<6571 6223 5469 5139 5083 5075>,
			<6666 6297 5498 5128 5063 5054>,
			<6800 6378 5534 5125 5059 5051>,
			<7141 6521 5646 5139 5064 5056>,
			<8151 6741 5818 5169 5077 5068>,
			<8151 6741 5818 5169 5077 5068>,
			<8151 6741 5818 5169 5077 5068>;
	};

};
